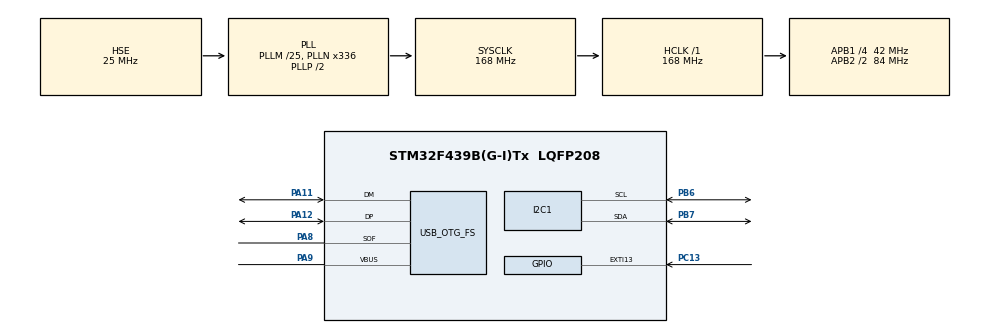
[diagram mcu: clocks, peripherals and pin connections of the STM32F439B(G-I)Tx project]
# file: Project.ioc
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Mcu.Family=STM32F4
Mcu.Name=STM32F439B(G-I)Tx
Mcu.Package=LQFP208
NVIC.EXTI15_10_IRQn=true\:0\:0\:false
NVIC.OTG_FS_IRQn=true\:5\:0\:true
NVIC.PriorityGroup=NVIC_PRIORITYGROUP_4
PA11.GPIO_Mode=GPIO_MODE_AF_PP
PA11.GPIO_PuPd=GPIO_NOPULL
PA11.GPIO_Speed=GPIO_SPEED_HIGH
PA11.Mode=Host_Only
PA11.Signal=USB_OTG_FS_DM
PA12.GPIO_Mode=GPIO_MODE_AF_PP
PA12.GPIO_PuPd=GPIO_NOPULL
PA12.GPIO_Speed=GPIO_SPEED_HIGH
PA12.Mode=Host_Only
PA12.Signal=USB_OTG_FS_DP
PA8.GPIO_Mode=GPIO_MODE_AF_PP
PA8.GPIO_PuPd=GPIO_NOPULL
PA8.GPIO_Speed=GPIO_SPEED_HIGH
PA8.Mode=Activate_SOF_FS
PA8.Signal=USB_OTG_FS_SOF
PA9.Mode=Activate_VBUS
PA9.Signal=USB_OTG_FS_VBUS
PB6.GPIO_Mode=GPIO_MODE_AF_OD
PB6.GPIO_PuPdOD=GPIO_PULLUP
PB6.GPIO_Speed=GPIO_SPEED_HIGH
PB6.Mode=I2C
PB6.Signal=I2C1_SCL
PB7.GPIO_Mode=GPIO_MODE_AF_OD
PB7.GPIO_PuPdOD=GPIO_PULLUP
PB7.GPIO_Speed=GPIO_SPEED_HIGH
PB7.Mode=I2C
PB7.Signal=I2C1_SDA
PC13.GPIO_ModeDefaultEXTI=GPIO_MODE_IT_RISING
PC13.GPIO_PuPd=GPIO_NOPULL
PC13.Signal=GPXTI13
PH0/OSC_IN.Mode=HSE-External-Oscillator
PH0/OSC_IN.Signal=RCC_OSC_IN
PH1/OSC_OUT.Mode=HSE-External-Oscillator
PH1/OSC_OUT.Signal=RCC_OSC_OUT
ProjectManager.TargetToolchain=EWARM
RCC.48MHZClocksFreq_Value=48000000
RCC.AHBFreq_Value=168000000
RCC.APB1CLKDivider=RCC_HCLK_DIV4
RCC.APB1Freq_Value=42000000
RCC.APB1TimCLKDivider=1
RCC.APB1TimFreq_Value=42000000
RCC.APB2CLKDivider=RCC_HCLK_DIV2
RCC.APB2Freq_Value=84000000
RCC.APB2TimCLKDivider=1
RCC.APB2TimFreq_Value=84000000
RCC.CortexFreq_Value=21000000
RCC.HCLKFreq_Value=168000000
RCC.HSE_VALUE=25000000
RCC.HSI_VALUE=16000000
RCC.LSE_VALUE=32768
RCC.PLLM=25
RCC.PLLN=336
RCC.PLLQ=7
RCC.SYSCLKFreq_VALUE=168000000
RCC.SYSCLKSource=RCC_SYSCLKSOURCE_PLLCLK
RCC.VCOOutputFreq_Value=336000000
USB_HOST.USBH_DEBUG_LEVEL-MSC_FS=3
USB_HOST.USBH_HandleTypeDef-MSC_FS=hUsbHostFS
USB_HOST.VirtualModeFS-MSC_FS=Msc
USB_OTG_FS.phy_itface-Host_Only=HCD_PHY_EMBEDDED
USB_OTG_FS.use_external_vbus=ENABLE
VP_USB_HOST_VS_USB_HOST_MSC_FS.Mode=MSC_FS

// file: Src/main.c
/**
  ******************************************************************************
  * File Name          : main.c
  * Date               : 20/02/2015 18:04:00
  * Description        : Main program body
  ******************************************************************************
  *
  * COPYRIGHT(c) 2015 STMicroelectronics
  *
  * Redistribution and use in source and binary forms, with or without modification,
  * are permitted provided that the following conditions are met:
  *   1. Redistributions of source code must retain the above copyright notice,
  *      this list of conditions and the following disclaimer.
  *   2. Redistributions in binary form must reproduce the above copyright notice,
  *      this list of conditions and the following disclaimer in the documentation
  *      and/or other materials provided with the distribution.
  *   3. Neither the name of STMicroelectronics nor the names of its contributors
  *      may be used to endorse or promote products derived from this software
  *      without specific prior written permission.
  *
  * THIS SOFTWARE IS PROVIDED BY THE COPYRIGHT HOLDERS AND CONTRIBUTORS "AS IS"
  * AND ANY EXPRESS OR IMPLIED WARRANTIES, INCLUDING, BUT NOT LIMITED TO, THE
  * IMPLIED WARRANTIES OF MERCHANTABILITY AND FITNESS FOR A PARTICULAR PURPOSE ARE
  * DISCLAIMED. IN NO EVENT SHALL THE COPYRIGHT HOLDER OR CONTRIBUTORS BE LIABLE
  * FOR ANY DIRECT, INDIRECT, INCIDENTAL, SPECIAL, EXEMPLARY, OR CONSEQUENTIAL
  * DAMAGES (INCLUDING, BUT NOT LIMITED TO, PROCUREMENT OF SUBSTITUTE GOODS OR
  * SERVICES; LOSS OF USE, DATA, OR PROFITS; OR BUSINESS INTERRUPTION) HOWEVER
  * CAUSED AND ON ANY THEORY OF LIABILITY, WHETHER IN CONTRACT, STRICT LIABILITY,
  * OR TORT (INCLUDING NEGLIGENCE OR OTHERWISE) ARISING IN ANY WAY OUT OF THE USE
  * OF THIS SOFTWARE, EVEN IF ADVISED OF THE POSSIBILITY OF SUCH DAMAGE.
  *
  ******************************************************************************
  */

#include "stm32f4xx_hal.h"
#include "usb_host.h"

I2C_HandleTypeDef hi2c1;

void SystemClock_Config(void);
static void MX_GPIO_Init(void);
static void MX_I2C1_Init(void);
void MX_USB_HOST_Process(void);

int main(void)
{

  /* MCU Configuration----------------------------------------------------------*/

  /* Reset of all peripherals, Initializes the Flash interface and the Systick. */
  HAL_Init();

  /* Configure the system clock */
  SystemClock_Config();

  /* Initialize all configured peripherals */
  MX_GPIO_Init();
  MX_I2C1_Init();
  MX_USB_HOST_Init();

  /* USER CODE BEGIN 3 */
  /* Infinite loop */
  while (1)
  {

    MX_USB_HOST_Process();

  }
  /* USER CODE END 3 */

}

/** System Clock Configuration
*/
void SystemClock_Config(void)
{

  RCC_OscInitTypeDef RCC_OscInitStruct;
  RCC_ClkInitTypeDef RCC_ClkInitStruct;

  __PWR_CLK_ENABLE();

  __HAL_PWR_VOLTAGESCALING_CONFIG(PWR_REGULATOR_VOLTAGE_SCALE1);

  RCC_OscInitStruct.OscillatorType = RCC_OSCILLATORTYPE_HSE;
  RCC_OscInitStruct.HSEState = RCC_HSE_ON;
  RCC_OscInitStruct.PLL.PLLState = RCC_PLL_ON;
  RCC_OscInitStruct.PLL.PLLSource = RCC_PLLSOURCE_HSE;
  RCC_OscInitStruct.PLL.PLLM = 25;
  RCC_OscInitStruct.PLL.PLLN = 336;
  RCC_OscInitStruct.PLL.PLLP = RCC_PLLP_DIV2;
  RCC_OscInitStruct.PLL.PLLQ = 7;
  HAL_RCC_OscConfig(&RCC_OscInitStruct);

  RCC_ClkInitStruct.ClockType = RCC_CLOCKTYPE_SYSCLK|RCC_CLOCKTYPE_PCLK1
                              |RCC_CLOCKTYPE_PCLK2;
  RCC_ClkInitStruct.SYSCLKSource = RCC_SYSCLKSOURCE_PLLCLK;
  RCC_ClkInitStruct.AHBCLKDivider = RCC_SYSCLK_DIV1;
  RCC_ClkInitStruct.APB1CLKDivider = RCC_HCLK_DIV4;
  RCC_ClkInitStruct.APB2CLKDivider = RCC_HCLK_DIV2;
  HAL_RCC_ClockConfig(&RCC_ClkInitStruct, FLASH_LATENCY_5);

}

/* I2C1 init function */
void MX_I2C1_Init(void)
{

  hi2c1.Instance = I2C1;
  hi2c1.Init.ClockSpeed = 100000;
  hi2c1.Init.DutyCycle = I2C_DUTYCYCLE_2;
  hi2c1.Init.OwnAddress1 = 0;
  hi2c1.Init.AddressingMode = I2C_ADDRESSINGMODE_7BIT;
  hi2c1.Init.DualAddressMode = I2C_DUALADDRESS_DISABLED;
  hi2c1.Init.OwnAddress2 = 0;
  hi2c1.Init.GeneralCallMode = I2C_GENERALCALL_DISABLED;
  hi2c1.Init.NoStretchMode = I2C_NOSTRETCH_DISABLED;
  HAL_I2C_Init(&hi2c1);

}

/** Configure pins as
        * Analog
        * Input
        * Output
        * EVENT_OUT
        * EXTI
*/
void MX_GPIO_Init(void)
{

  GPIO_InitTypeDef GPIO_InitStruct;

  /* GPIO Ports Clock Enable */
  __GPIOC_CLK_ENABLE();
  __GPIOH_CLK_ENABLE();
  __GPIOA_CLK_ENABLE();
  __GPIOB_CLK_ENABLE();

  /*Configure GPIO pin : PC13 */
  GPIO_InitStruct.Pin = GPIO_PIN_13;
  GPIO_InitStruct.Mode = GPIO_MODE_IT_RISING;
  GPIO_InitStruct.Pull = GPIO_NOPULL;
  HAL_GPIO_Init(GPIOC, &GPIO_InitStruct);

  /* EXTI interrupt init*/
  HAL_NVIC_SetPriority(EXTI15_10_IRQn, 4, 0);
  HAL_NVIC_EnableIRQ(EXTI15_10_IRQn);

}

/************************ (C) COPYRIGHT STMicroelectronics *****END OF FILE****/
